# BL808 register map
File version: 0.1
Registers are access not given, no defined reset value unless marked. A register's access mark holds for its fields unless they carry their own. Offsets are from the block's base; [hi:lo] are bit positions; {n}, {i} and the like mark numbered series.

## SF_CTRL
Base 0x2000B000
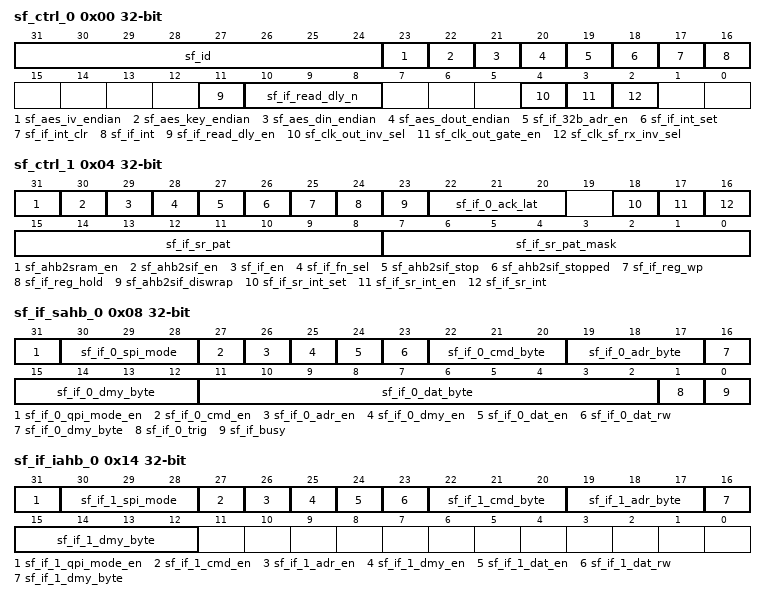
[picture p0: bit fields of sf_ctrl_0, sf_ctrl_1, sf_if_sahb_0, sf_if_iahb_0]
0x00 sf_ctrl_0
  [31:24] sf_id rw, [23] sf_aes_iv_endian rw, [22] sf_aes_key_endian rw, [21] sf_aes_din_endian rw, [20] sf_aes_dout_endian rw, [19] sf_if_32b_adr_en rw, [18] sf_if_int_set rw, [17] sf_if_int_clr rw, [16] sf_if_int ro, [11] sf_if_read_dly_en rw, [10:8] sf_if_read_dly_n rw, [4] sf_clk_out_inv_sel rw, [3] sf_clk_out_gate_en rw, [2] sf_clk_sf_rx_inv_sel rw
0x04 sf_ctrl_1
  [31] sf_ahb2sram_en rw, [30] sf_ahb2sif_en rw, [29] sf_if_en rw, [28] sf_if_fn_sel rw, [27] sf_ahb2sif_stop rw, [26] sf_ahb2sif_stopped ro, [25] sf_if_reg_wp rw, [24] sf_if_reg_hold rw, [23] sf_ahb2sif_diswrap rw, [22:20] sf_if_0_ack_lat rw, [18] sf_if_sr_int_set rw, [17] sf_if_sr_int_en rw, [16] sf_if_sr_int ro, [15:8] sf_if_sr_pat rw, [7:0] sf_if_sr_pat_mask rw
0x08 sf_if_sahb_0 access per field
  [31] sf_if_0_qpi_mode_en rw, [30:28] sf_if_0_spi_mode rw, [27] sf_if_0_cmd_en rw, [26] sf_if_0_adr_en rw, [25] sf_if_0_dmy_en rw, [24] sf_if_0_dat_en rw, [23] sf_if_0_dat_rw rw, [22:20] sf_if_0_cmd_byte rw, [19:17] sf_if_0_adr_byte rw, [16:12] sf_if_0_dmy_byte rw, [11:2] sf_if_0_dat_byte rw, [1] sf_if_0_trig rw, [0] sf_if_busy ro
0x0C sf_if_sahb_1 rw
  [31:0] sf_if_0_cmd_buf_0
0x10 sf_if_sahb_2 rw
  [31:0] sf_if_0_cmd_buf_1
0x14 sf_if_iahb_0
  [31] sf_if_1_qpi_mode_en rw, [30:28] sf_if_1_spi_mode rw, [27] sf_if_1_cmd_en rw, [26] sf_if_1_adr_en rw, [25] sf_if_1_dmy_en rw, [24] sf_if_1_dat_en rw, [23] sf_if_1_dat_rw rw, [22:20] sf_if_1_cmd_byte rw, [19:17] sf_if_1_adr_byte rw, [16:12] sf_if_1_dmy_byte rw
0x18 sf_if_iahb_1 rw
  [31:0] sf_if_1_cmd_buf_0
0x1C sf_if_iahb_2 rw
  [31:0] sf_if_1_cmd_buf_1
0x20 sf_if_status_0 ro
  [31:0] sf_if_status_0
0x24 sf_if_status_1 ro
  [31:0] sf_if_status_1
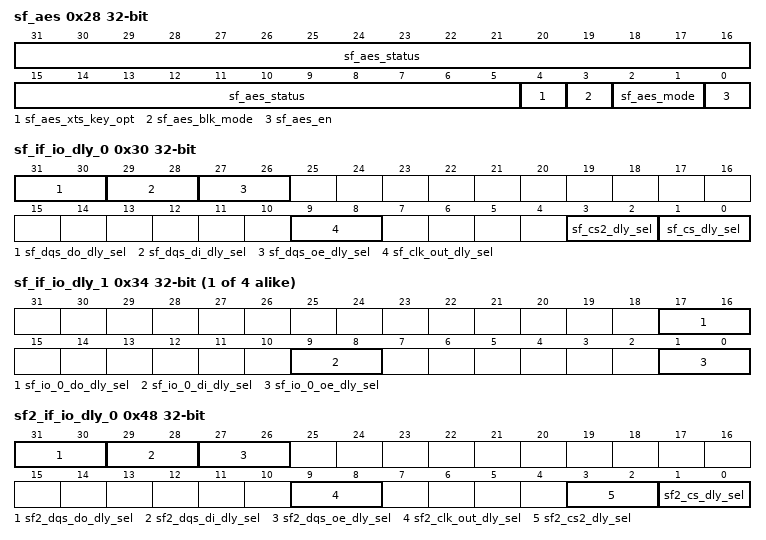
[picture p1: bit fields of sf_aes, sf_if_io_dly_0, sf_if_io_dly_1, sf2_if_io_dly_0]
0x28 sf_aes access per field
  [31:5] sf_aes_status ro, [4] sf_aes_xts_key_opt rw, [3] sf_aes_blk_mode rw, [2:1] sf_aes_mode rw, [0] sf_aes_en rw
0x2C sf_ahb2sif_status ro
  [31:0] sf_ahb2sif_status
0x30 sf_if_io_dly_0
  [31:30] sf_dqs_do_dly_sel rw, [29:28] sf_dqs_di_dly_sel rw, [27:26] sf_dqs_oe_dly_sel rw, [9:8] sf_clk_out_dly_sel rw, [3:2] sf_cs2_dly_sel rw, [1:0] sf_cs_dly_sel rw
{0x30+4i} sf_if_io_dly_{i} (i=1..4)
  [17:16] sf_io_{i-1}_do_dly_sel rw, [9:8] sf_io_{i-1}_di_dly_sel rw, [1:0] sf_io_{i-1}_oe_dly_sel rw
0x44 sf_reserved rw
  [31:0] sf_reserved
0x48 sf2_if_io_dly_0
  [31:30] sf2_dqs_do_dly_sel rw, [29:28] sf2_dqs_di_dly_sel rw, [27:26] sf2_dqs_oe_dly_sel rw, [9:8] sf2_clk_out_dly_sel rw, [3:2] sf2_cs2_dly_sel rw, [1:0] sf2_cs_dly_sel rw
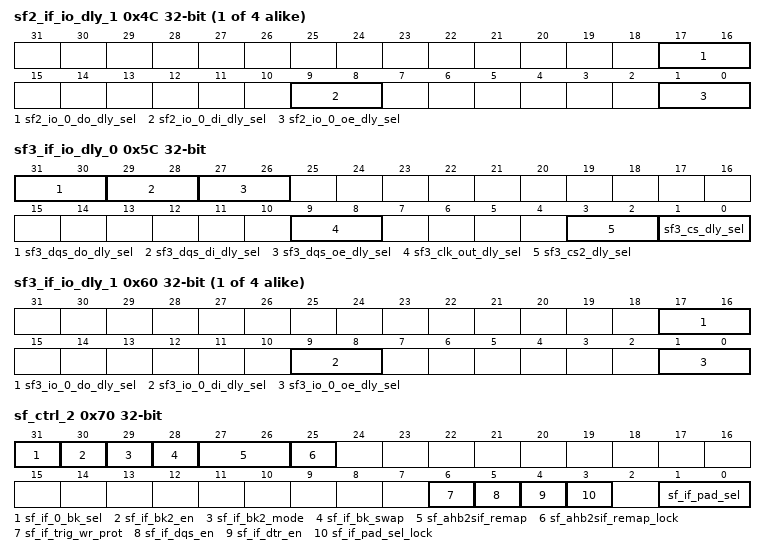
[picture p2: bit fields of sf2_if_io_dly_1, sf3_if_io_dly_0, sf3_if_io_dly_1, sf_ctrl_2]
{0x48+4i} sf2_if_io_dly_{i} (i=1..4)
  [17:16] sf2_io_{i-1}_do_dly_sel rw, [9:8] sf2_io_{i-1}_di_dly_sel rw, [1:0] sf2_io_{i-1}_oe_dly_sel rw
0x5C sf3_if_io_dly_0
  [31:30] sf3_dqs_do_dly_sel rw, [29:28] sf3_dqs_di_dly_sel rw, [27:26] sf3_dqs_oe_dly_sel rw, [9:8] sf3_clk_out_dly_sel rw, [3:2] sf3_cs2_dly_sel rw, [1:0] sf3_cs_dly_sel rw
{0x5C+4i} sf3_if_io_dly_{i} (i=1..4)
  [17:16] sf3_io_{i-1}_do_dly_sel rw, [9:8] sf3_io_{i-1}_di_dly_sel rw, [1:0] sf3_io_{i-1}_oe_dly_sel rw
0x70 sf_ctrl_2
  [31] sf_if_0_bk_sel rw, [30] sf_if_bk2_en rw, [29] sf_if_bk2_mode rw, [28] sf_if_bk_swap rw, [27:26] sf_ahb2sif_remap rw, [25] sf_ahb2sif_remap_lock rw, [6] sf_if_trig_wr_prot rw, [5] sf_if_dqs_en rw, [4] sf_if_dtr_en rw, [3] sf_if_pad_sel_lock rw, [1:0] sf_if_pad_sel rw
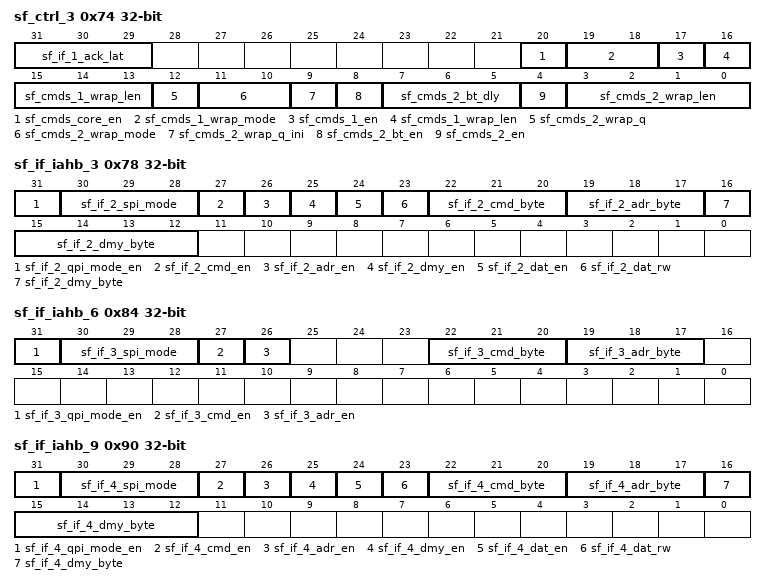
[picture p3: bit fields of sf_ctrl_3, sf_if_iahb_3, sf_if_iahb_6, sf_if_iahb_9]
0x74 sf_ctrl_3
  [31:29] sf_if_1_ack_lat rw, [20] sf_cmds_core_en rw, [19:18] sf_cmds_1_wrap_mode rw, [17] sf_cmds_1_en rw, [16:13] sf_cmds_1_wrap_len rw, [12] sf_cmds_2_wrap_q ro, [11:10] sf_cmds_2_wrap_mode rw, [9] sf_cmds_2_wrap_q_ini rw, [8] sf_cmds_2_bt_en rw, [7:5] sf_cmds_2_bt_dly rw, [4] sf_cmds_2_en rw, [3:0] sf_cmds_2_wrap_len rw
0x78 sf_if_iahb_3
  [31] sf_if_2_qpi_mode_en rw, [30:28] sf_if_2_spi_mode rw, [27] sf_if_2_cmd_en rw, [26] sf_if_2_adr_en rw, [25] sf_if_2_dmy_en rw, [24] sf_if_2_dat_en rw, [23] sf_if_2_dat_rw rw, [22:20] sf_if_2_cmd_byte rw, [19:17] sf_if_2_adr_byte rw, [16:12] sf_if_2_dmy_byte rw
0x7C sf_if_iahb_4 rw
  [31:0] sf_if_2_cmd_buf_0
0x80 sf_if_iahb_5 rw
  [31:0] sf_if_2_cmd_buf_1
0x84 sf_if_iahb_6
  [31] sf_if_3_qpi_mode_en rw, [30:28] sf_if_3_spi_mode rw, [27] sf_if_3_cmd_en rw, [26] sf_if_3_adr_en rw, [22:20] sf_if_3_cmd_byte rw, [19:17] sf_if_3_adr_byte rw
0x88 sf_if_iahb_7 rw
  [31:0] sf_if_3_cmd_buf_0
0x8C sf_if_iahb_8 rw
  [31:0] sf_if_3_cmd_buf_1
0x90 sf_if_iahb_9
  [31] sf_if_4_qpi_mode_en rw, [30:28] sf_if_4_spi_mode rw, [27] sf_if_4_cmd_en rw, [26] sf_if_4_adr_en rw, [25] sf_if_4_dmy_en rw, [24] sf_if_4_dat_en rw, [23] sf_if_4_dat_rw rw, [22:20] sf_if_4_cmd_byte rw, [19:17] sf_if_4_adr_byte rw, [16:12] sf_if_4_dmy_byte rw
0x94 sf_if_iahb_10 rw
  [31:0] sf_if_4_cmd_buf_0
0x98 sf_if_iahb_11 rw
  [31:0] sf_if_4_cmd_buf_1
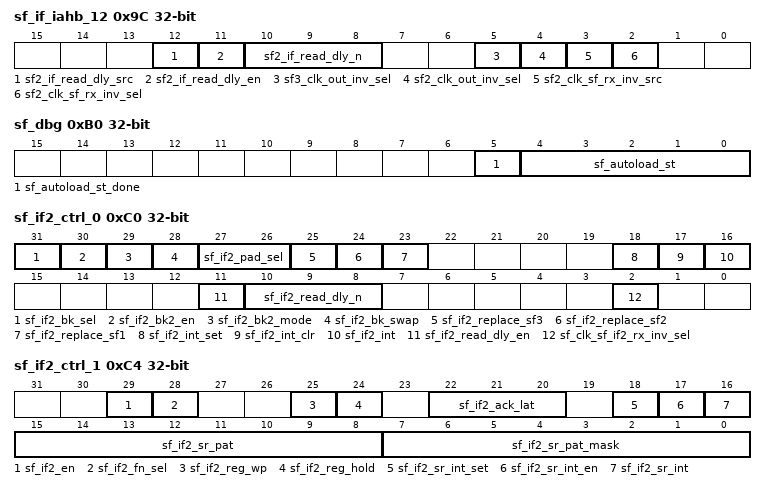
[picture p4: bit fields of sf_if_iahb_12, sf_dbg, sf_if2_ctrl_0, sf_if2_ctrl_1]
0x9C sf_if_iahb_12
  [12] sf2_if_read_dly_src rw, [11] sf2_if_read_dly_en rw, [10:8] sf2_if_read_dly_n rw, [5] sf3_clk_out_inv_sel rw, [4] sf2_clk_out_inv_sel rw, [3] sf2_clk_sf_rx_inv_src rw, [2] sf2_clk_sf_rx_inv_sel rw
0xA0 sf_id0_offset
  [27:0] sf_id0_offset rw
0xA4 sf_id1_offset
  [27:0] sf_id1_offset rw
0xA8 sf_bk2_id0_offset
  [27:0] sf_bk2_id0_offset rw
0xAC sf_bk2_id1_offset
  [27:0] sf_bk2_id1_offset rw
0xB0 sf_dbg
  [5] sf_autoload_st_done ro, [4:0] sf_autoload_st ro
0xC0 sf_if2_ctrl_0
  [31] sf_if2_bk_sel rw, [30] sf_if2_bk2_en rw, [29] sf_if2_bk2_mode rw, [28] sf_if2_bk_swap rw, [27:26] sf_if2_pad_sel rw, [25] sf_if2_replace_sf3 rw, [24] sf_if2_replace_sf2 rw, [23] sf_if2_replace_sf1 rw, [18] sf_if2_int_set rw, [17] sf_if2_int_clr rw, [16] sf_if2_int ro, [11] sf_if2_read_dly_en rw, [10:8] sf_if2_read_dly_n rw, [2] sf_clk_sf_if2_rx_inv_sel rw
0xC4 sf_if2_ctrl_1
  [29] sf_if2_en rw, [28] sf_if2_fn_sel rw, [25] sf_if2_reg_wp rw, [24] sf_if2_reg_hold rw, [22:20] sf_if2_ack_lat rw, [18] sf_if2_sr_int_set rw, [17] sf_if2_sr_int_en rw, [16] sf_if2_sr_int ro, [15:8] sf_if2_sr_pat rw, [7:0] sf_if2_sr_pat_mask rw
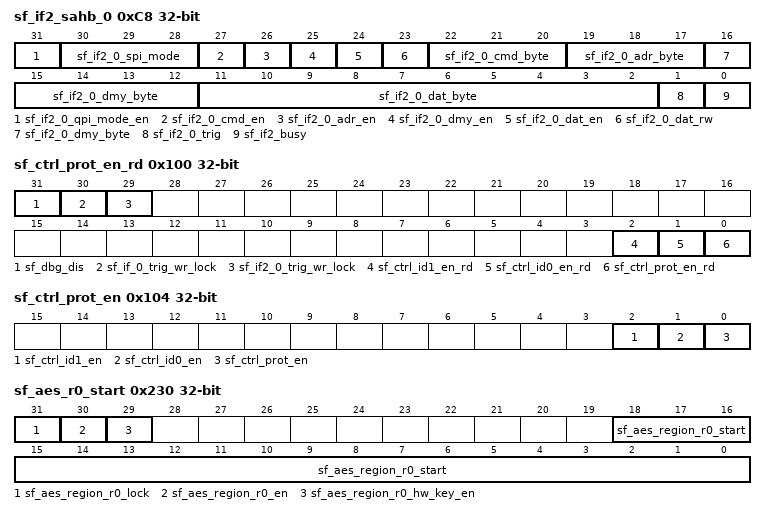
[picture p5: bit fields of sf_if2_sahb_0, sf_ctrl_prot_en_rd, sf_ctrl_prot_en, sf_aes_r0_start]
0xC8 sf_if2_sahb_0 access per field
  [31] sf_if2_0_qpi_mode_en rw, [30:28] sf_if2_0_spi_mode rw, [27] sf_if2_0_cmd_en rw, [26] sf_if2_0_adr_en rw, [25] sf_if2_0_dmy_en rw, [24] sf_if2_0_dat_en rw, [23] sf_if2_0_dat_rw rw, [22:20] sf_if2_0_cmd_byte rw, [19:17] sf_if2_0_adr_byte rw, [16:12] sf_if2_0_dmy_byte rw, [11:2] sf_if2_0_dat_byte rw, [1] sf_if2_0_trig rw, [0] sf_if2_busy ro
0xCC sf_if2_sahb_1 rw
  [31:0] sf_if2_0_cmd_buf_0
0xD0 sf_if2_sahb_2 rw
  [31:0] sf_if2_0_cmd_buf_1
0x100 sf_ctrl_prot_en_rd
  [31] sf_dbg_dis ro, [30] sf_if_0_trig_wr_lock ro, [29] sf_if2_0_trig_wr_lock ro, [2] sf_ctrl_id1_en_rd ro, [1] sf_ctrl_id0_en_rd ro, [0] sf_ctrl_prot_en_rd ro
0x104 sf_ctrl_prot_en
  [2] sf_ctrl_id1_en rw, [1] sf_ctrl_id0_en rw, [0] sf_ctrl_prot_en rw
{0x200+4i} sf_aes_key_r0_{i} rw (i=0..7)
  [31:0] sf_aes_key_r0_{i}
{0x220+4i} sf_aes_iv_r0_w{i} rw (i=0..3)
  [31:0] sf_aes_iv_r0_w{i}
0x230 sf_aes_r0_start
  [31] sf_aes_region_r0_lock rw, [30] sf_aes_region_r0_en rw, [29] sf_aes_region_r0_hw_key_en rw, [18:0] sf_aes_region_r0_start rw
0x234 sf_aes_r0_end
  [18:0] sf_aes_region_r0_end rw
{0x280+4i} sf_aes_key_r1_{i} rw (i=0..7)
  [31:0] sf_aes_key_r1_{i}
{0x2A0+4i} sf_aes_iv_r1_w{i} rw (i=0..3)
  [31:0] sf_aes_iv_r1_w{i}
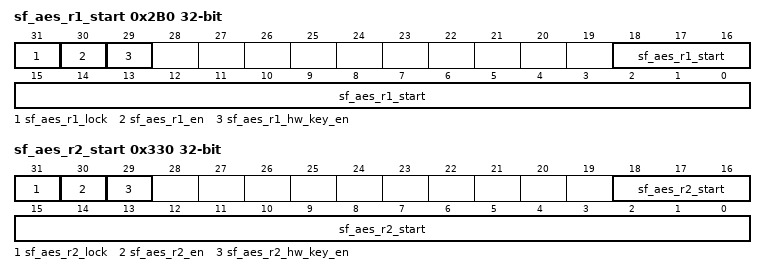
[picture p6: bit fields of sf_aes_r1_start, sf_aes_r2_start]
0x2B0 sf_aes_r1_start
  [31] sf_aes_r1_lock rw, [30] sf_aes_r1_en rw, [29] sf_aes_r1_hw_key_en rw, [18:0] sf_aes_r1_start rw
0x2B4 sf_aes_r1_end
  [18:0] sf_aes_r1_end rw
{0x300+4i} sf_aes_key_r2_{i} rw (i=0..7)
  [31:0] sf_aes_key_r2_{i}
{0x320+4i} sf_aes_iv_r2_w{i} rw (i=0..3)
  [31:0] sf_aes_iv_r2_w{i}
0x330 sf_aes_r2_start
  [31] sf_aes_r2_lock rw, [30] sf_aes_r2_en rw, [29] sf_aes_r2_hw_key_en rw, [18:0] sf_aes_r2_start rw
0x334 sf_aes_r2_end
  [18:0] sf_aes_r2_end rw
